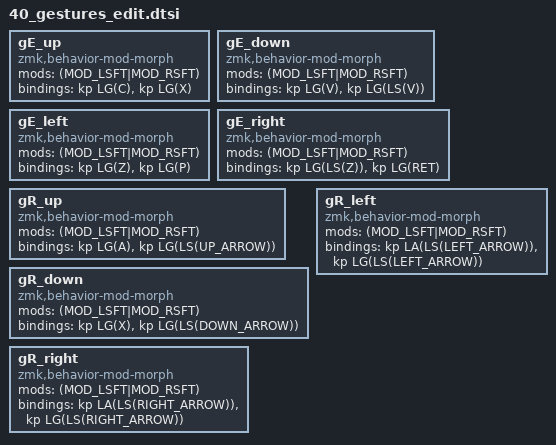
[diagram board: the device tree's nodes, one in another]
/* ============================================================
 * 40_gestures_edit.dtsi — 編集・選択ジェスチャー (gE / gR)
 *
 * behaviors { } の内側でインクルードされる。
 *   gE: コピー / ペースト / アンドゥ / リドゥ 系（E キー長押し）
 *   gR: テキスト選択範囲操作系（R キー長押し）
 * ============================================================ */

/* --- gE: Sharp Nail — 編集操作 --- */

gE_up: gE_up {
    compatible = "zmk,behavior-mod-morph";
    #binding-cells = <0>;
    mods = <(MOD_LSFT|MOD_RSFT)>;
    bindings = <&kp LG(C)>, <&kp LG(X)>;
};

gE_down: gE_down {
    compatible = "zmk,behavior-mod-morph";
    #binding-cells = <0>;
    mods = <(MOD_LSFT|MOD_RSFT)>;
    bindings = <&kp LG(V)>, <&kp LG(LS(V))>;
};

gE_left: gE_left {
    compatible = "zmk,behavior-mod-morph";
    #binding-cells = <0>;
    mods = <(MOD_LSFT|MOD_RSFT)>;
    bindings = <&kp LG(Z)>, <&kp LG(P)>;
};

gE_right: gE_right {
    compatible = "zmk,behavior-mod-morph";
    #binding-cells = <0>;
    mods = <(MOD_LSFT|MOD_RSFT)>;
    bindings = <&kp LG(LS(Z))>, <&kp LG(RET)>;
};

/* --- gR: Vorpal Strike — 選択範囲操作 --- */

gR_up: gR_up {
    compatible = "zmk,behavior-mod-morph";
    #binding-cells = <0>;
    mods = <(MOD_LSFT|MOD_RSFT)>;
    bindings = <&kp LG(A)>, <&kp LG(LS(UP_ARROW))>;
};

gR_down: gR_down {
    compatible = "zmk,behavior-mod-morph";
    #binding-cells = <0>;
    mods = <(MOD_LSFT|MOD_RSFT)>;
    bindings = <&kp LG(X)>, <&kp LG(LS(DOWN_ARROW))>;
};

gR_left: gR_left {
    compatible = "zmk,behavior-mod-morph";
    #binding-cells = <0>;
    mods = <(MOD_LSFT|MOD_RSFT)>;
    bindings = <&kp LA(LS(LEFT_ARROW))>, <&kp LG(LS(LEFT_ARROW))>;
};

gR_right: gR_right {
    compatible = "zmk,behavior-mod-morph";
    #binding-cells = <0>;
    mods = <(MOD_LSFT|MOD_RSFT)>;
    bindings = <&kp LA(LS(RIGHT_ARROW))>, <&kp LG(LS(RIGHT_ARROW))>;
};
